AUTOSAR XML (schema 314)
package /ComponentType
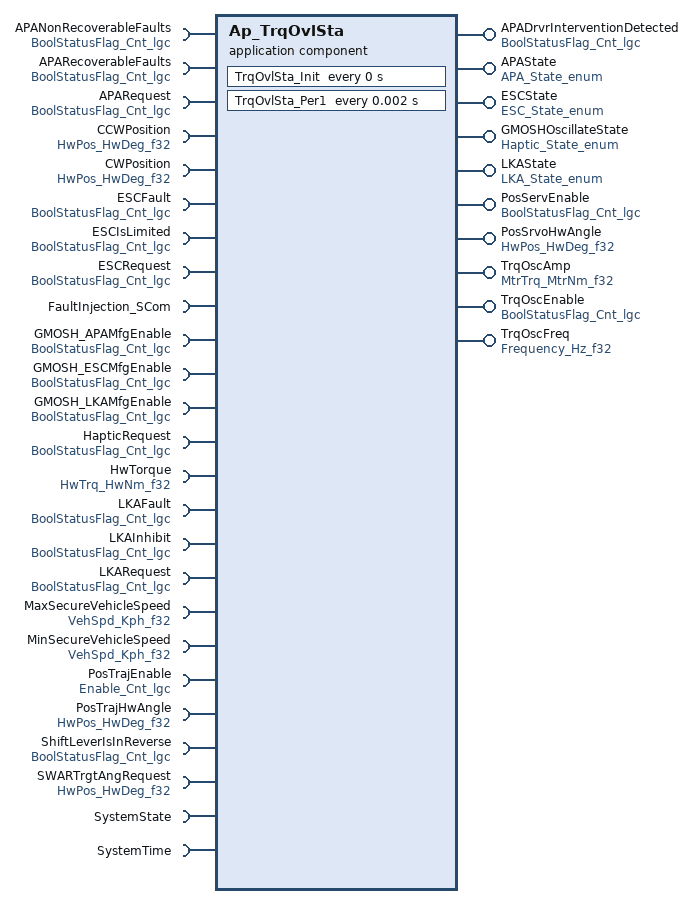
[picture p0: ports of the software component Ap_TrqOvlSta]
  application software component type Ap_TrqOvlSta
    10 x provide port:
      APADrvrInterventionDetected: unqueued-sender-com-spec{data-element=Cnt_lgc, can-invalidate=false, init-value=D_FALSE_CNT_LGC}, provided-interface=BoolStatusFlag_Cnt_lgc
      APAState: unqueued-sender-com-spec{data-element=State_enum, can-invalidate=false, init-value=D_APASTATEINIT_CNT_U08}, provided-interface=APA_State_enum
      ESCState: unqueued-sender-com-spec{data-element=State_enum, can-invalidate=false, init-value=D_ESCSTATEINIT_CNT_U08}, provided-interface=ESC_State_enum
      GMOSHOscillateState: unqueued-sender-com-spec{data-element=State_enum, can-invalidate=false, init-value=D_HAPTICSTATEINIT_CNT_U08}, provided-interface=Haptic_State_enum
      LKAState: unqueued-sender-com-spec{data-element=State_enum, can-invalidate=false, init-value=D_LKASTATEINIT_CNT_U08}, provided-interface=LKA_State_enum
      PosServEnable: unqueued-sender-com-spec{data-element=Cnt_lgc, can-invalidate=false, init-value=D_FALSE_CNT_LGC}, provided-interface=BoolStatusFlag_Cnt_lgc
      PosSrvoHwAngle: unqueued-sender-com-spec{data-element=HwDeg_f32, can-invalidate=false, init-value=D_ZERO_ULS_F32}, provided-interface=HwPos_HwDeg_f32
      TrqOscAmp: unqueued-sender-com-spec{data-element=MtrNm_f32, can-invalidate=false, init-value=D_ZERO_ULS_F32}, provided-interface=MtrTrq_MtrNm_f32
      TrqOscEnable: unqueued-sender-com-spec{data-element=Cnt_lgc, can-invalidate=false, init-value=D_FALSE_CNT_LGC}, provided-interface=BoolStatusFlag_Cnt_lgc
      TrqOscFreq: unqueued-sender-com-spec{data-element=Hz_f32, can-invalidate=false, init-value=D_ZERO_ULS_F32}, provided-interface=Frequency_Hz_f32
    25 x require port:
      APANonRecoverableFaults: unqueued-receiver-com-spec{data-element=Cnt_lgc, init-value=D_FALSE_CNT_LGC}, required-interface=BoolStatusFlag_Cnt_lgc
      APARecoverableFaults: unqueued-receiver-com-spec{data-element=Cnt_lgc, init-value=D_FALSE_CNT_LGC}, required-interface=BoolStatusFlag_Cnt_lgc
      APARequest: unqueued-receiver-com-spec{data-element=Cnt_lgc, init-value=D_FALSE_CNT_LGC}, required-interface=BoolStatusFlag_Cnt_lgc
      CCWPosition: unqueued-receiver-com-spec{data-element=HwDeg_f32, init-value=D_ZERO_ULS_F32}, required-interface=HwPos_HwDeg_f32
      CWPosition: unqueued-receiver-com-spec{data-element=HwDeg_f32, init-value=D_ZERO_ULS_F32}, required-interface=HwPos_HwDeg_f32
      ESCFault: unqueued-receiver-com-spec{data-element=Cnt_lgc, init-value=D_FALSE_CNT_LGC}, required-interface=BoolStatusFlag_Cnt_lgc
      ESCIsLimited: unqueued-receiver-com-spec{data-element=Cnt_lgc, init-value=D_FALSE_CNT_LGC}, required-interface=BoolStatusFlag_Cnt_lgc
      ESCRequest: unqueued-receiver-com-spec{data-element=Cnt_lgc, init-value=D_FALSE_CNT_LGC}, required-interface=BoolStatusFlag_Cnt_lgc
      FaultInjection_SCom: client-com-spec=FltInjection, required-interface=FaultInjection_SCom
      GMOSH_APAMfgEnable: unqueued-receiver-com-spec{data-element=Cnt_lgc, init-value=D_FALSE_CNT_LGC}, required-interface=BoolStatusFlag_Cnt_lgc
      GMOSH_ESCMfgEnable: unqueued-receiver-com-spec{data-element=Cnt_lgc, init-value=D_FALSE_CNT_LGC}, required-interface=BoolStatusFlag_Cnt_lgc
      GMOSH_LKAMfgEnable: unqueued-receiver-com-spec{data-element=Cnt_lgc, init-value=D_FALSE_CNT_LGC}, required-interface=BoolStatusFlag_Cnt_lgc
      HapticRequest: unqueued-receiver-com-spec{data-element=Cnt_lgc, init-value=D_FALSE_CNT_LGC}, required-interface=BoolStatusFlag_Cnt_lgc
      HwTorque: unqueued-receiver-com-spec{data-element=HwNm_f32, init-value=D_ZERO_ULS_F32}, required-interface=HwTrq_HwNm_f32
      LKAFault: unqueued-receiver-com-spec{data-element=Cnt_lgc, init-value=D_FALSE_CNT_LGC}, required-interface=BoolStatusFlag_Cnt_lgc
      LKAInhibit: unqueued-receiver-com-spec{data-element=Cnt_lgc, init-value=D_FALSE_CNT_LGC}, required-interface=BoolStatusFlag_Cnt_lgc
      LKARequest: unqueued-receiver-com-spec{data-element=Cnt_lgc, init-value=D_FALSE_CNT_LGC}, required-interface=BoolStatusFlag_Cnt_lgc
      MaxSecureVehicleSpeed: unqueued-receiver-com-spec{data-element=Kph_f32, init-value=D_ZERO_ULS_F32}, required-interface=VehSpd_Kph_f32
      MinSecureVehicleSpeed: unqueued-receiver-com-spec{data-element=Kph_f32, init-value=D_ZERO_ULS_F32}, required-interface=VehSpd_Kph_f32
      PosTrajEnable: unqueued-receiver-com-spec{data-element=Cnt_lgc, init-value=D_FALSE_CNT_LGC}, required-interface=Enable_Cnt_lgc
      PosTrajHwAngle: unqueued-receiver-com-spec{data-element=HwDeg_f32, init-value=D_ZERO_ULS_F32}, required-interface=HwPos_HwDeg_f32
      ShiftLeverIsInReverse: unqueued-receiver-com-spec{data-element=Cnt_lgc, init-value=D_FALSE_CNT_LGC}, required-interface=BoolStatusFlag_Cnt_lgc
      SWARTrgtAngRequest: unqueued-receiver-com-spec{data-element=HwDeg_f32, init-value=D_ZERO_ULS_F32}, required-interface=HwPos_HwDeg_f32
      SystemState: required-interface=SystemState
      SystemTime: required-interface=SystemTime
        required-com-specs:
          DtrmnElapsedTime_mS_u16
          DtrmnElapsedTime_mS_u32
          DtrmnElapsedTime_uS_u16
          DtrmnElapsedTime_uS_u32
          GetSystemTime_mS_u32
          GetSystemTime_uS_u32
  internal behavior Ap_TrqOvlSta_InternalBehavior: component=Ap_TrqOvlSta
    timing event TrqOvlSta_InitEvent: start-on-event=TrqOvlSta_Init, period=0
    timing event TMT_TrqOvlSta_Per1: mode-dependency=dependent-on-mode=[SystemState.Mode.DISABLE, SystemState.Mode.OFF, SystemState.Mode.WARMINIT], start-on-event=TrqOvlSta_Per1, period=0.002
    port-api-options:
      enable-take-address=false, indirect-api=false, port=APADrvrInterventionDetected
      enable-take-address=false, indirect-api=false, port=APANonRecoverableFaults
      enable-take-address=false, indirect-api=false, port=APARecoverableFaults
      enable-take-address=false, indirect-api=false, port=APARequest
      enable-take-address=false, indirect-api=false, port=APAState
      enable-take-address=false, indirect-api=false, port=CCWPosition
      enable-take-address=false, indirect-api=false, port=CWPosition
      enable-take-address=false, indirect-api=false, port=ESCFault
      enable-take-address=false, indirect-api=false, port=ESCIsLimited
      enable-take-address=false, indirect-api=false, port=ESCRequest
      enable-take-address=false, indirect-api=false, port=ESCState
      enable-take-address=false, indirect-api=false, port=FaultInjection_SCom
      enable-take-address=false, indirect-api=false, port=GMOSH_APAMfgEnable
      enable-take-address=false, indirect-api=false, port=GMOSH_ESCMfgEnable
      enable-take-address=false, indirect-api=false, port=GMOSH_LKAMfgEnable
      enable-take-address=false, indirect-api=false, port=GMOSHOscillateState
      enable-take-address=false, indirect-api=false, port=HapticRequest
      enable-take-address=false, indirect-api=false, port=HwTorque
      enable-take-address=false, indirect-api=false, port=LKAFault
      enable-take-address=false, indirect-api=false, port=LKAInhibit
      enable-take-address=false, indirect-api=false, port=LKARequest
      enable-take-address=false, indirect-api=false, port=LKAState
      enable-take-address=false, indirect-api=false, port=MaxSecureVehicleSpeed
      enable-take-address=false, indirect-api=false, port=MinSecureVehicleSpeed
      enable-take-address=false, indirect-api=false, port=PosServEnable
      enable-take-address=false, indirect-api=false, port=PosSrvoHwAngle
      enable-take-address=false, indirect-api=false, port=PosTrajEnable
      enable-take-address=false, indirect-api=false, port=PosTrajHwAngle
      enable-take-address=false, indirect-api=false, port=ShiftLeverIsInReverse
      enable-take-address=false, indirect-api=false, port=SWARTrgtAngRequest
      enable-take-address=false, indirect-api=false, port=SystemState
      enable-take-address=false, indirect-api=false, port=SystemTime
      enable-take-address=false, indirect-api=false, port=TrqOscAmp
      enable-take-address=false, indirect-api=false, port=TrqOscEnable
      enable-take-address=false, indirect-api=false, port=TrqOscFreq
    runnable TrqOvlSta_Init
      sync call SC_SystemTime_GetSystemTime_mS_u32: operation=SystemTime.GetSystemTime_mS_u32, timeout=0
    runnable TrqOvlSta_Per1
      22 x data read access:
        READ_APANonRecoverableFaults_Cnt_lgc: data-element=APANonRecoverableFaults.Cnt_lgc
        READ_APARecoverableFaults_Cnt_lgc: data-element=APARecoverableFaults.Cnt_lgc
        READ_APARequest_Cnt_lgc: data-element=APARequest.Cnt_lgc
        READ_CCWPosition_HwDeg_f32: data-element=CCWPosition.HwDeg_f32
        READ_CWPosition_HwDeg_f32: data-element=CWPosition.HwDeg_f32
        READ_ESCFault_Cnt_lgc: data-element=ESCFault.Cnt_lgc
        READ_ESCIsLimited_Cnt_lgc: data-element=ESCIsLimited.Cnt_lgc
        READ_ESCRequest_Cnt_lgc: data-element=ESCRequest.Cnt_lgc
        READ_GMOSH_APAMfgEnable_Cnt_lgc: data-element=GMOSH_APAMfgEnable.Cnt_lgc
        READ_GMOSH_ESCMfgEnable_Cnt_lgc: data-element=GMOSH_ESCMfgEnable.Cnt_lgc
        READ_GMOSH_LKAMfgEnable_Cnt_lgc: data-element=GMOSH_LKAMfgEnable.Cnt_lgc
        READ_HapticRequest_Cnt_lgc: data-element=HapticRequest.Cnt_lgc
        READ_HwTorque_HwNm_f32: data-element=HwTorque.HwNm_f32
        READ_LKAFault_Cnt_lgc: data-element=LKAFault.Cnt_lgc
        READ_LKAInhibit_Cnt_lgc: data-element=LKAInhibit.Cnt_lgc
        READ_LKARequest_Cnt_lgc: data-element=LKARequest.Cnt_lgc
        READ_MaxSecureVehicleSpeed_Kph_f32: data-element=MaxSecureVehicleSpeed.Kph_f32
        READ_MinSecureVehicleSpeed_Kph_f32: data-element=MinSecureVehicleSpeed.Kph_f32
        READ_PosTrajEnable_Cnt_lgc: data-element=PosTrajEnable.Cnt_lgc
        READ_PosTrajHwAngle_HwDeg_f32: data-element=PosTrajHwAngle.HwDeg_f32
        READ_ShiftLeverIsInReverse_Cnt_lgc: data-element=ShiftLeverIsInReverse.Cnt_lgc
        READ_SWARTrgtAngRequest_HwDeg_f32: data-element=SWARTrgtAngRequest.HwDeg_f32
      10 x data write access:
        WRITE_APADrvrInterventionDetected_Cnt_lgc: data-element=APADrvrInterventionDetected.Cnt_lgc
        WRITE_APAState_State_enum: data-element=APAState.State_enum
        WRITE_ESCState_State_enum: data-element=ESCState.State_enum
        WRITE_GMOSHOscillateState_State_enum: data-element=GMOSHOscillateState.State_enum
        WRITE_LKAState_State_enum: data-element=LKAState.State_enum
        WRITE_PosServEnable_Cnt_lgc: data-element=PosServEnable.Cnt_lgc
        WRITE_PosSrvoHwAngle_HwDeg_f32: data-element=PosSrvoHwAngle.HwDeg_f32
        WRITE_TrqOscAmp_MtrNm_f32: data-element=TrqOscAmp.MtrNm_f32
        WRITE_TrqOscEnable_Cnt_lgc: data-element=TrqOscEnable.Cnt_lgc
        WRITE_TrqOscFreq_Hz_f32: data-element=TrqOscFreq.Hz_f32
      sync call SC_FaultInjection_SCom_FltInjection: operation=FaultInjection_SCom.FltInjection, timeout=0
      sync call SC_SystemTime_DtrmnElapsedTime_mS_u16: operation=SystemTime.DtrmnElapsedTime_mS_u16, timeout=0
      sync call SC_SystemTime_GetSystemTime_mS_u32: operation=SystemTime.GetSystemTime_mS_u32, timeout=0
  swc implementation Ap_TrqOvlSta_Implementation: behavior=Ap_TrqOvlSta_InternalBehavior
    code-descriptors:
      code Code: type=SRC
